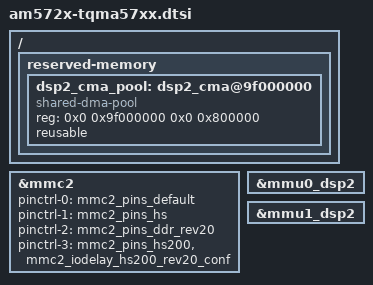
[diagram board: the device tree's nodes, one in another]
// SPDX-License-Identifier: GPL-2.0-or-later OR MIT
/*
 * Device Tree file for TQ-Systems TQMa572x SoM.
 *
 * Copyright (c) 2020-2022 TQ-Systems GmbH <linux@ew.tq-group.com>, D-82229 Seefeld, Germany.
 * Author: Michael Krummsdorf, Matthias Schiffer
 */

#include "am5728.dtsi"
#include "am57xx-tqma57xx.dtsi"
#include "dra74x-mmc-iodelay.dtsi"

/ {
	reserved-memory {
		dsp2_cma_pool: dsp2_cma@9f000000 {
			compatible = "shared-dma-pool";
			reg = <0x0 0x9f000000 0x0 0x800000>;
			reusable;
		};
	};
};

&mmc2 {
	pinctrl-names = "default", "hs", "ddr_1_8v", "hs200_1_8v";
	pinctrl-0 = <&mmc2_pins_default>;
	pinctrl-1 = <&mmc2_pins_hs>;
	pinctrl-2 = <&mmc2_pins_ddr_rev20>;
	pinctrl-3 = <&mmc2_pins_hs200 &mmc2_iodelay_hs200_rev20_conf>;
};

&mmu0_dsp2 {
	status = "okay";
};

&mmu1_dsp2 {
	status = "okay";
};
